# AT32UC3A0128 device description
Architecture: AVR32_UC3; Family: AVR UC3
Registers are 32-bit, read-write, reset 0x0 unless marked. A register's access mark holds for its fields unless they carry their own. Offsets are from the block's base; [hi:lo] are bit positions; {n}, {i} and the like mark numbered series.

## MACB — Ethernet MAC
Instances: MACB 0xfffe1800
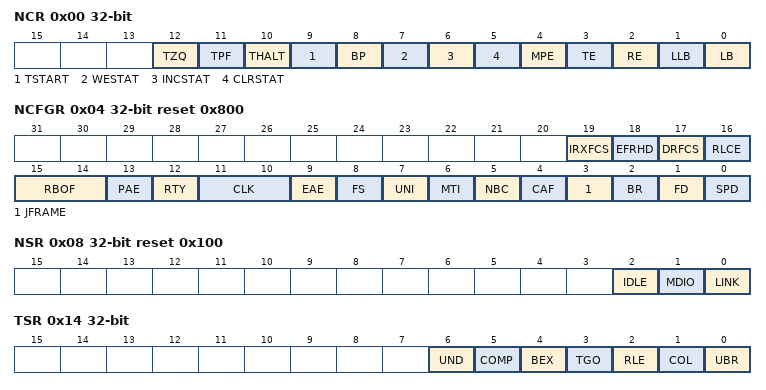
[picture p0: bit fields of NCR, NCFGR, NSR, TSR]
0x00 NCR — Network Control Register
  [12] TZQ — Transmit zero quantum pause frame
  [11] TPF — Transmit pause frame
  [10] THALT — Transmit halt
  [9] TSTART — Start transmission
  [8] BP — Back pressure
  [7] WESTAT — Write enable for statistics registers
  [6] INCSTAT — Increment statistics registers
  [5] CLRSTAT — Clear statistics registers
  [4] MPE — Management port enable
  [3] TE — Transmit enable
  [2] RE — Receive enable
  [1] LLB — Loopback local
  [0] LB — Loopback
0x04 NCFGR reset 0x800 — Network Configuration Register
  [19] IRXFCS — Ignore RX FCS
  [18] EFRHD — Enable frames to be received in half-duplex mode while transmitting.
  [17] DRFCS — Discard receive FCS
  [16] RLCE — Receive length field checking enable
  [15:14] RBOF — Receive buffer offset
  [13] PAE — Pause enable
  [12] RTY — Retry test
  [11:10] CLK — MDC Clock divider
    0=DIV8; 1=DIV16; 2=DIV32; 3=DIV64
  [9] EAE — External address match enable
  [8] FS — Frame size
  [7] UNI — Unicast hash enable
  [6] MTI — Multicast hash enable
  [5] NBC — No broadcast
  [4] CAF — Copy all frames
  [3] JFRAME — Jumbo frames
  [2] BR — Bitrate
  [1] FD — Full duplex
  [0] SPD — Speed
0x08 NSR ro reset 0x100 — Network Status Register
  [2] IDLE — PHY management logic idle
  [1] MDIO
  [0] LINK
0x14 TSR — Transmit Status Register
  [6] UND — Transmit underrun
  [5] COMP — Transmit complete
  [4] BEX — Buffers exhausted mid frame
  [3] TGO — Transmit go
  [2] RLE — Retry limit exceeded
  [1] COL — Collision occurred
  [0] UBR — Used bit read
0x18 RBQP — Receive Buffer Queue Pointer
0x1C TBQP — Transmit Buffer Queue Pointer
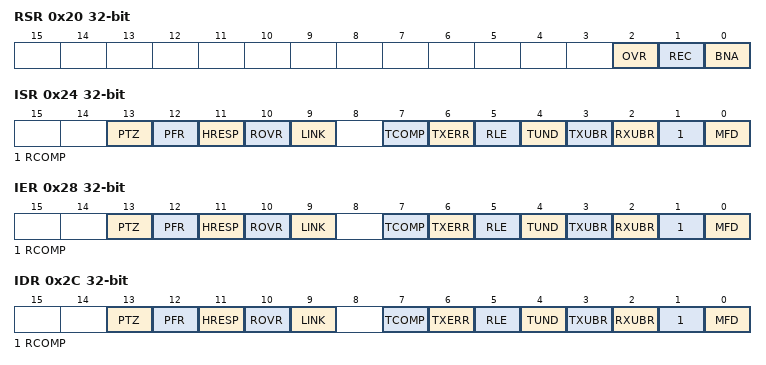
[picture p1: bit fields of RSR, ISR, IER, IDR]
0x20 RSR — Receive Status Register
  [2] OVR — Receive overrun
  [1] REC — Frame received
  [0] BNA — Buffer not available
0x24 ISR — Interrupt Status Register
  [13] PTZ — Pause time zero
  [12] PFR — Pause frame received
  [11] HRESP — hresp not OK
  [10] ROVR — Receive overrun
  [9] LINK — Link change
  [7] TCOMP — Transmit complete
  [6] TXERR — Transmit Error
  [5] RLE — Retry limit exceeded
  [4] TUND — Ethernet transmit buffer underrun
  [3] TXUBR — TX used bit read
  [2] RXUBR — RX used bit read
  [1] RCOMP — Receive complete
  [0] MFD — Management frame done
0x28 IER wo reset not defined — Interrupt Enable Register
  [13] PTZ — Pause Time Zero
  [12] PFR — Pause Frame Received
  [11] HRESP — HRESP not OK
  [10] ROVR — receive overrun
  [9] LINK — Link change
  [7] TCOMP — transmit complete
  [6] TXERR — Transmit Error
  [5] RLE — Retry Limit Exceeded
  [4] TUND — Ethernet Transmit Buffer Underrun
  [3] TXUBR — Transmit Used Bit Read
  [2] RXUBR — Receive Used Bit Read
  [1] RCOMP — Receive Complete
  [0] MFD — Management Frame sent
0x2C IDR wo reset not defined — Interrupt Disable Register
  [13] PTZ — Pause Time Zero
  [12] PFR — Pause Frame Received
  [11] HRESP — Hresp not OK
  [10] ROVR — Receive Overrun
  [9] LINK — Link change
  [7] TCOMP — Transmit Complete
  [6] TXERR — Transmit Error
  [5] RLE — Retry Limit Exceeded
  [4] TUND — Ethernet Transmit Buffer Underrun
  [3] TXUBR — Transmit Used Bit Read
  [2] RXUBR — Receive Used Bit Read
  [1] RCOMP — Receive Complete
  [0] MFD — Management Frame sent
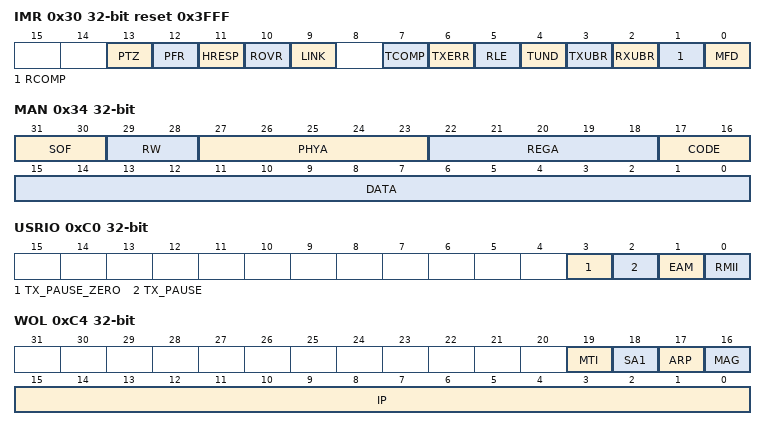
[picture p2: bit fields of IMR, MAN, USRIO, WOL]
0x30 IMR ro reset 0x3FFF — Interrupt Mask Register
  [13] PTZ — Pause Time Zero
  [12] PFR — Pause Frame Received
  [11] HRESP — Hresp not OK
  [10] ROVR — Receive Overrun
  [9] LINK — Link change
  [7] TCOMP — Transmit Complete
  [6] TXERR — Transmit Error
  [5] RLE — Retry Limit Exceeded
  [4] TUND — Ethernet Transmit Buffer Underrun
  [3] TXUBR — Transmit Used Bit Read
  [2] RXUBR — Receive used bit read
  [1] RCOMP — Receive Complete
  [0] MFD — Management Frame sent
0x34 MAN — PHY Maintenance Register
  [31:30] SOF — Start of frame
  [29:28] RW — Read/Write
  [27:23] PHYA — PHY address
  [22:18] REGA — Register address
  [17:16] CODE
  [15:0] DATA
0x38 PTR ro — Pause Time Register
  [15:0] PTIME — Pause time
0x3C PFR — Pause Frames Received
  [15:0] PFROK — Pause frames received OK
0x40 FTO — Pause Transmitted OK
  [23:0] FTOK — Frames Transmitted OK
0x44 SCF — Single Collision Frames
  [15:0] SCF — Single collision frames
0x48 MCF — Multiple Collision Frames
  [15:0] MCF — Multiple collision frames
0x4C FRO — Frames Received OK
  [23:0] FROK — Frames received OK
0x50 FCSE — Frame Check Sequence Errors
  [7:0] FCSE — Frame check sequence errors
0x54 ALE — Alignment Errors
  [7:0] ALE — Alignment errors
0x58 DTF — Deferred Transmission Frames
  [15:0] DTF — Deferred transmission frames
0x5C LCOL — Late Collisions
  [7:0] LCOL — Late collisions
0x60 EXCOL — Excessive Collisions
  [7:0] EXCOL — Excessive collisions
0x64 TUND — Transmit Underrun Errors
  [7:0] TUND — Transmit underruns
0x68 CSE — Carrier Sense Errors
  [7:0] CSE — Carrier sense errors
0x6C RRE — Receive Resource Errors
  [15:0] RRE — Receive resource errors
0x70 ROVR — Receive Overrun Errors
  [7:0] ROVR — Receive overruns
0x74 RSE — Receive Symbol Errors
  [7:0] RSE — Receive symbol errors
0x78 ELE — Excessive Length Errors
  [7:0] EXL — Excessive length frames
0x7C RJA — Receive Jabbers
  [7:0] RJB — Receive jabbers
0x80 USF — Undersize Frames
  [7:0] USF — Undersize frames
0x84 STE — SQE Test Errors
  [7:0] SQER — SQE test errors
0x88 RLE — Received Length Field Mismatch
  [7:0] RLFM — Receive length field mismatch
0x8C TPF — Transmitted Pause Frames
  [15:0] TPF — Transmitted pause frames
0x90 HRB — Hash Register Bottom [31:0]
  [31:0] Addr — Address
0x94 HRT — Hash Register Top [63:32]
  [31:0] ADDR — Address
{0x90+8i} SA{i}B (i=1..4) — Specific Address {i} Bottom
  [31:0] ADDR — Address
{0x94+8i} SA{i}T (i=1..4) — Specific Address {i} Top
  [15:0] ADDR — Address
0xB8 TID — Type ID Checking
  [15:0] TID — Type ID checking.
0xBC TPQ reset 0xFFFF — Transmit Pause Quantum
  [15:0] TPQ — Transmit pause quantum
0xC0 USRIO — User Input/Output Register
  [3] TX_PAUSE_ZERO, [2] TX_PAUSE, [1] EAM, [0] RMII
0xC4 WOL — Wake on LAN
  [19] MTI — Multicast hash event enable
  [18] SA1 — Specific address register 1 event enable
  [17] ARP — ARP request event enable
  [16] MAG — Magic packet event enable
  [15:0] IP — ARP request IP address
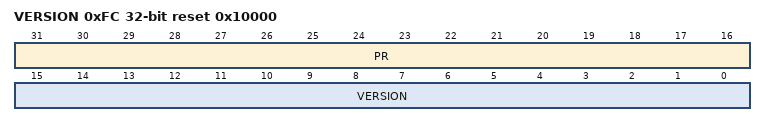
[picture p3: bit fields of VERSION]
0xFC VERSION ro reset 0x10000 — Revision Register
  [31:16] PR — Part reference
  [15:0] VERSION — Revision reference
